# GD32H7xx register map
File version: 1.0
CPU: CM7 r1p2, little endian, MPU, FPU, 4 interrupt priority bits
Registers are 32-bit, read-write, reset 0x0 unless marked. A register's access mark holds for its fields unless they carry their own. Offsets are from the block's base; [hi:lo] are bit positions; {n}, {i} and the like mark numbered series; 'fields as' and 'values as' point back to an identical list.

## FWDGT — free watchdog timer
Base 0x58004800
0x00 CTL wo — Control register
  [15:0] CMD — Key value
0x04 PSC — Prescaler register
  [2:0] PSC — Prescaler divider
0x08 RLD reset 0xFFF — Reload register
  [11:0] RLD — Watchdog counter reload value
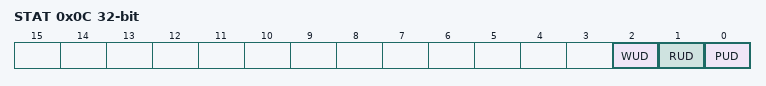
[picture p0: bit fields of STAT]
0x0C STAT ro — Status register
  [2] WUD — Watchdog counter window value update
  [1] RUD — Watchdog counter reload value update
  [0] PUD — Watchdog prescaler value update
0x10 WND reset 0xFFF — Window register
  [11:0] WND — Watchdog counter window value

## GPIOA — General-purpose I/Os
Base 0x58020000
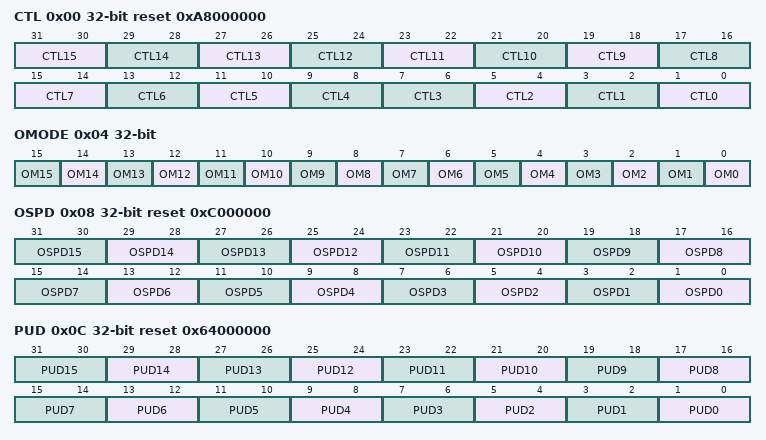
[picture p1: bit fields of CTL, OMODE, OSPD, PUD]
0x00 CTL reset 0xA8000000 — GPIO port control register
  [2n+1:2n] CTL{n} (n=7..15) — Port x configuration bits (x = {n})
  [13:12] CTL6 — Port x configuration bits (x = 6 )
  [11:10] CTL5 — Port x configuration bits (x = 5)
  [9:8] CTL4 — Port x configuration bits (x = 4 )
  [2n+1:2n] CTL{n} (n=0..3) — Port x configuration bits (x = {n})
0x04 OMODE — GPIO port output mode register
  [n] OM{n} (n=0..15) — Port {n} output mode bit
0x08 OSPD reset 0xC000000 — GPIO port output speed register
  [2n+1:2n] OSPD{n} (n=0..15) — Port {n} output max speed bits
0x0C PUD reset 0x64000000 — GPIO port pull-up/pull-down register
  [2n+1:2n] PUD{n} (n=0..15) — Port {n} pull-up or pull-down bits
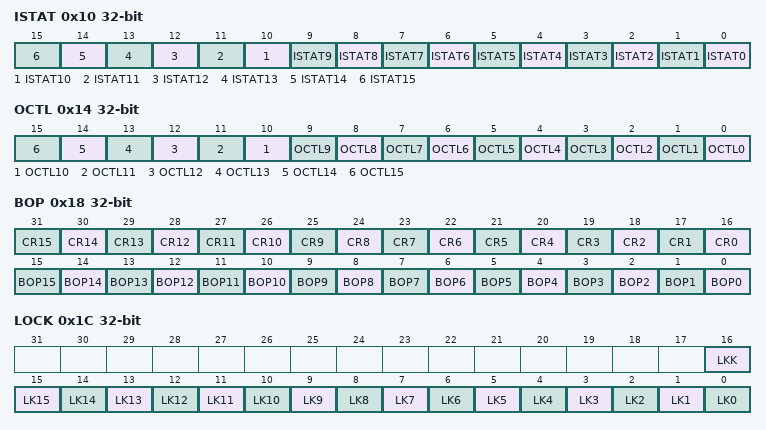
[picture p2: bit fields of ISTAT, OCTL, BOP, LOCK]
0x10 ISTAT ro — GPIO port input status register
  [n] ISTAT{n} (n=0..15) — Port input status (y = {n})
0x14 OCTL — GPIO port output control register
  [n] OCTL{n} (n=0..15) — Port output control (y = {n})
0x18 BOP wo — GPIO port bit operate register
  [n+16] CR{n} (n=0..15) — Port Clear bit {n}
  [n] BOP{n} (n=0..15) — Port Set bit {n}
0x1C LOCK — GPIO port configuration lock register
  [16] LKK — Lock sequence key
  [n] LK{n} (n=0..15) — Port Lock bit {n}
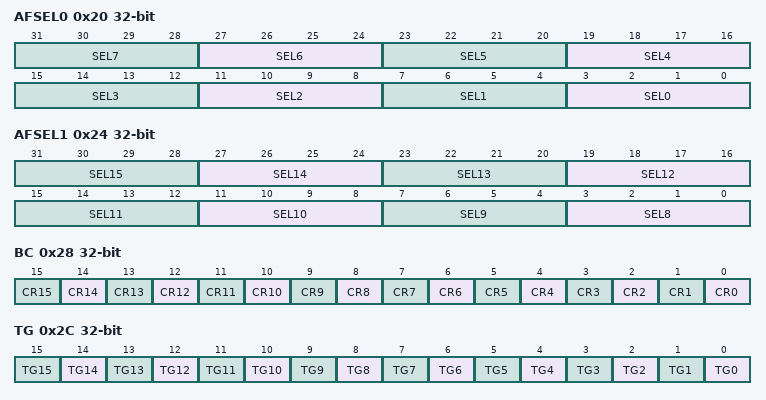
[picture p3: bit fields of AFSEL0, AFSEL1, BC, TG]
0x20 AFSEL0 — GPIO alternate function selected register 0
  [4n+3:4n] SEL{n} (n=0..7) — Port {n} alternate function selected
0x24 AFSEL1 — GPIO alternate function selected register 1
  [4n-29:4n-32] SEL{n} (n=8..15) — Port {n} alternate function selected
0x28 BC wo — Bit clear register
  [n] CR{n} (n=0..15) — Port cleat bit
0x2C TG wo — Port bit toggle register
  [n] TG{n} (n=0..15) — Port toggle bit
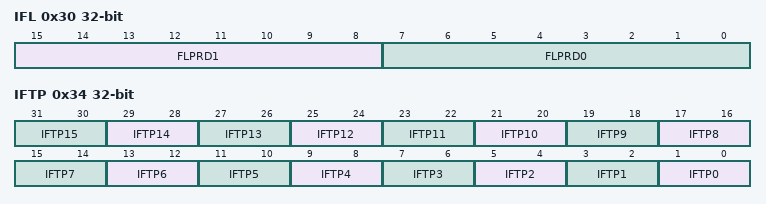
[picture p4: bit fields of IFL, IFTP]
0x30 IFL — Input filtering regist
  [15:8] FLPRD1 — Filter sampling period for GPIO8 to GPIO15:
  [7:0] FLPRD0 — Filter sampling period for GPIO1 to GPIO7:
0x34 IFTP — Input filtering type regist
  [2n+1:2n] IFTP{n} (n=0..15) — Pin {n} input filtering type bits

## GPIOB — General-purpose I/Os
Base 0x58020400
Registers as GPIOA; these are added or differ:
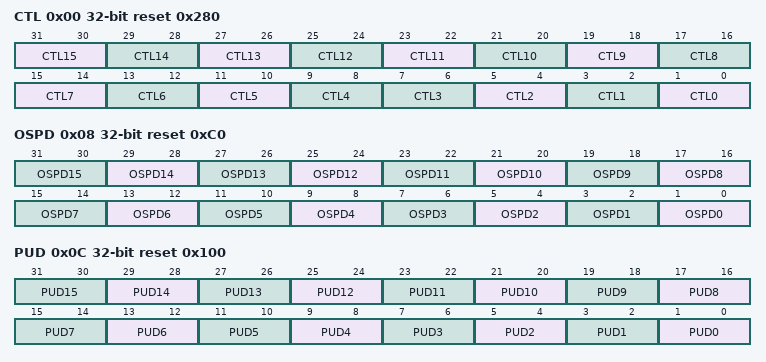
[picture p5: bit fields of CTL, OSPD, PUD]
0x00 CTL reset 0x280 — GPIO port control register
  fields as GPIOA.CTL
0x08 OSPD reset 0xC0 — GPIO port output speed register
  [2n+1:2n] OSPD{n} (n=0..15) — Port {n} output max speed bits
0x0C PUD reset 0x100 — GPIO port pull-up/pull-down register
  [2n+1:2n] PUD{n} (n=0..15) — Port {n} pull-up or pull-down bits

## GPIOC — General-purpose I/Os
Base 0x58020800
Same registers: GPIOD 0x58020C00, GPIOE 0x58021000, GPIOF 0x58021400, GPIOG 0x58021800, GPIOH 0x58021C00, GPIOJ 0x58022400, GPIOK 0x58022800
Registers as GPIOA; these are added or differ:
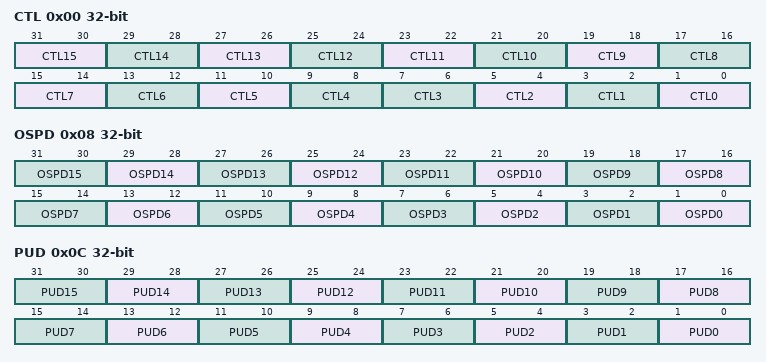
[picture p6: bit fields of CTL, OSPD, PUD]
0x00 CTL — GPIO port control register
  fields as GPIOA.CTL
0x08 OSPD — GPIO port output speed register
  [2n+1:2n] OSPD{n} (n=0..15) — Port {n} output max speed bits
0x0C PUD — GPIO port pull-up/pull-down register
  [2n+1:2n] PUD{n} (n=0..15) — Port {n} pull-up or pull-down bits

## HAU — HAU acceleration unit
Base 0x48021400
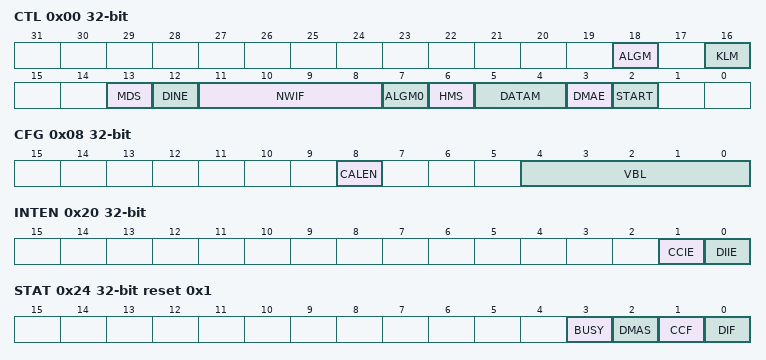
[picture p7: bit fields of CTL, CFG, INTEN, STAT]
0x00 CTL access per field — HAU control register
  [18] ALGM rw — Algorithm selection bit 1
  [16] KLM rw — Key length mode
  [13] MDS rw — Multiple DMA selection
  [12] DINE ro — DI register is not empty
  [11:8] NWIF ro — Number of words in IN FIFO
  [7] ALGM0 rw — Algorithm selection bit 0
  [6] HMS rw — HAU mode selection
  [5:4] DATAM rw — Data type mode
  [3] DMAE rw — DMA enable
  [2] START wo — Start message digest calculation
0x04 DI — HAU data input register
  [31:0] DI — Message data input
0x08 CFG access per field — HAU configuration register
  [8] CALEN wo — Digest calculation enable
  [4:0] VBL rw — Valid bits length in the last word
{0xC+4i} DO{i} ro (i=0..4) — HAU data output register
  [31:0] DO{i} — message digest result of hash algorithm
0x20 INTEN — HAU interrupt enable register
  [1] CCIE — calculation completion interrupt enable
  [0] DIIE — Data input interrupt enable
0x24 STAT ro reset 0x1 — HAU status and interrupt flag register
  [3] BUSY — Busy flag bit
  [2] DMAS — DMA status flag
  [1] CCF — Digest calculation completion flag
  [0] DIF — Data input flag
0xF8 CTXS0 reset 0x2 — Context switch register x
  [31:0] CTX0 — The complete internal status
{0xF8+4i} CTXS{i} (i=1..53) — Context switch register x
  [31:0] CTX{i} — The complete internal status
{0x310+4i} DO{i} ro (i=5..7) — HAU data output register
  [31:0] DO{i} — message digest result of hash algorithm
